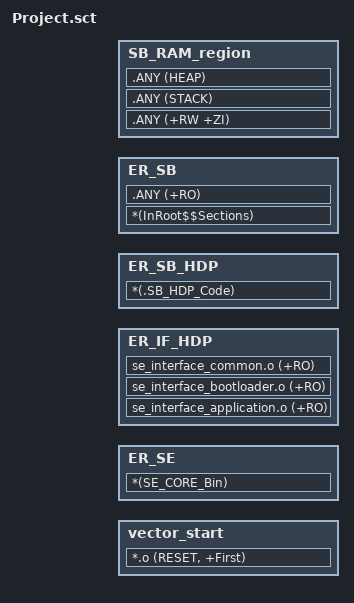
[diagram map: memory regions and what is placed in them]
#! armclang --target=arm-arm-none-eabi  -mcpu=cortex-m4 -E -xc
; *************************************************************
; *** Scatter-Loading Description File generated by uVision ***
; *************************************************************
#include "..\..\Linker_Common\MDK-ARM\mapping_sbsfu.h"
#include "..\..\Linker_Common\MDK-ARM\mapping_fwimg.h"

; *** regions needed by SBSFU project ***
LR_ROM_Vector ROM_START VECTOR_SIZE {
  vector_start ROM_START VECTOR_SIZE {
  *.o (RESET, +First)
  }
}

LR_SE SE_CODE_REGION_ROM_START SE_ROM_REGION_SIZE {
  ER_SE SE_CODE_REGION_ROM_START SE_ROM_REGION_SIZE {
  *(SE_CORE_Bin)
  }
}

LR_IF SE_IF_REGION_ROM_START SE_IF_ROM_REGION_SIZE {
  ER_IF_HDP SE_IF_REGION_ROM_START SE_IF_ROM_REGION_SIZE {
     se_interface_application.o (+RO)
	 se_interface_bootloader.o (+RO)
	 se_interface_common.o (+RO)
  }
}

LR_SB_HDP SB_HDP_REGION_ROM_START SB_HDP_ROM_REGION_SIZE {
  ER_SB_HDP SB_HDP_CODE_REGION_RAM_START SB_HDP_CODE_RAM_REGION_SIZE {
  *(.SB_HDP_Code)
  }
}

LR_SB SB_REGION_ROM_START SB_ROM_REGION_SIZE {  
  ER_SB SB_REGION_ROM_START SB_ROM_REGION_SIZE {
  *(InRoot$$Sections)
  .ANY (+RO)
  }
  SB_RAM_region SB_REGION_RAM_START SB_RAM_REGION_SIZE  {
  .ANY (+RW +ZI)
  .ANY (STACK)
  .ANY (HEAP)
  }
}
